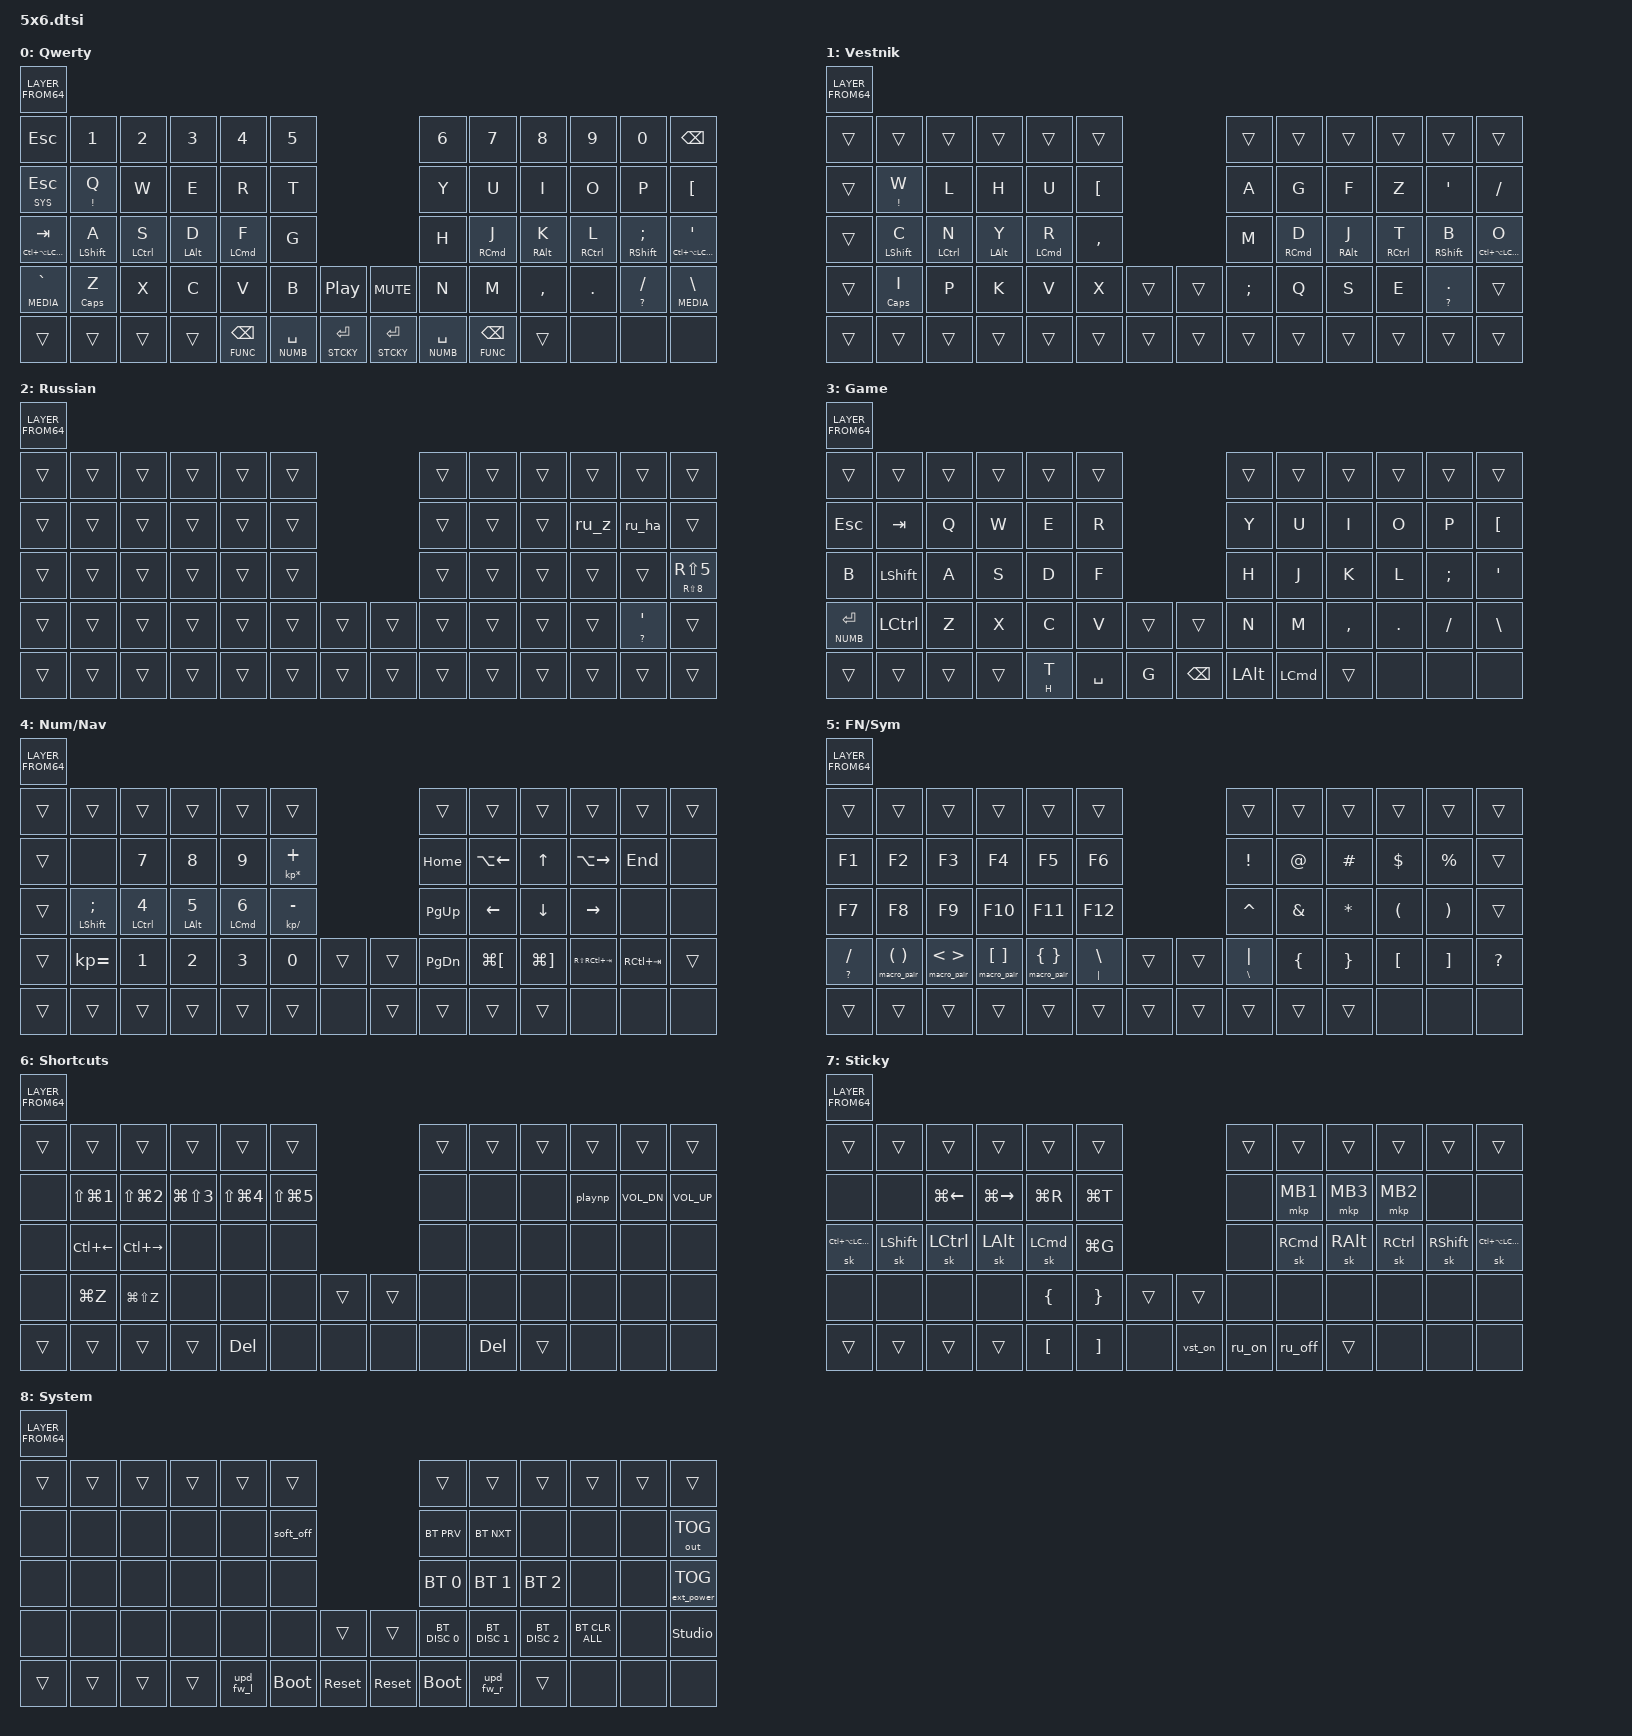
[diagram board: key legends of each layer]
// ZMK includes
#include <behaviors.dtsi>
#include <dt-bindings/zmk/bt.h>
#include <dt-bindings/zmk/ext_power.h>
#include <dt-bindings/zmk/keys.h>
#include <dt-bindings/zmk/pointing.h>
#include <dt-bindings/zmk/outputs.h>

#define ___    &trans
#define DFLT   0
#define VST    1
#define RU     2
#define GAME   3
#define NUMB   4
#define FUNC   5
#define MEDIA  6
#define STCKY  7
#define SYS    8

&lt { quick-tap-ms = <250>; };

&mt {
    hold-trigger-on-release;
    flavor = "balanced";
    quick-tap-ms = <250>;
};

&soft_off { hold-time-ms = <2000>; };

#include "combos.dtsi"
#include "macros.dtsi"
#include "behaviors.dtsi"

/ {
    sensors { triggers-per-rotation = <20>; };
};

/ {
    keymap {
        compatible = "zmk,keymap";

        default_layer {
            label = "Qwerty";
            bindings = < LAYER_FROM64( \
&kp ESCAPE,            &kp N1,        &kp N2,       &kp N3,      &kp N4,         &kp N5,                                              &kp N6,          &kp N7,           &kp N8,      &kp N9,       &kp N0,           &kp BACKSPACE,
&lt SYS ESC,           &mt EXCL Q,    &kp W,        &kp E,       &kp R,          &kp T,                                               &kp Y,           &kp U,            &kp I,       &kp O,        &kp P,            &kp LBKT,
&mt LC(LA(LCMD)) TAB,  &mtl LSHIFT A,  &mtl LCTRL S,  &mtl LALT D,  &mtl LCMD F, &kp G,                                               &kp H,           &mtr RCMD J,       &mtr RALT K,  &mtr RCTRL L,  &mtr RSHIFT SEMI,  &mt LC(LA(LCMD)) SQT,
&lt MEDIA GRAVE,       &mt CAPS Z,    &kp X,        &kp C,       &kp V,          &kp B,           &kp C_PLAY_PAUSE,  &kp K_MUTE,      &kp N,           &kp M,            &kp COMMA,   &kp DOT,      &mt QMARK SLASH,  &lt MEDIA BSLH,
___,                   ___,           ___,          ___,         &lt FUNC BSPC,  &lt NUMB SPACE,  &lt STCKY ENTER,  &lt STCKY ENTER,  &lt NUMB SPACE,  &lt FUNC BSPC,    ___,         &none,        &none,            &none
            )>;
            sensor-bindings =
              <&inc_dec_kp DOWN UP &inc_dec_kp RIGHT LEFT>;
        };

        vestnik {
            label = "Vestnik";
            bindings = < LAYER_FROM64( \
___,  ___,           ___,          ___,         ___,          ___,                   ___,       ___,           ___,         ___,           ___,            ___,
___,  &mt EXCL W,    &kp L,        &kp H,       &kp U,        &kp LBKT,              &kp A,     &kp G,         &kp F,       &kp Z,         &kp SQT,        &kp SLASH,
___,  &mtl LSHIFT C, &mtl LCTRL N, &mtl LALT Y, &mtl LCMD R,  &kp COMMA,             &kp M,     &mtr RCMD D,   &mtr RALT J, &mtr RCTRL T,  &mtr RSHIFT B,  &mt LC(LA(LCMD)) O,
___,  &mt CAPS I,    &kp P,        &kp K,       &kp V,        &kp X,     ___,  ___,  &kp SEMI,  &kp Q,         &kp S,       &kp E,         &mt QMARK DOT,  ___,
___,  ___,           ___,          ___,         ___,          ___,       ___,  ___,  ___,       ___,           ___,         ___,           ___,            ___
            )>;
            sensor-bindings =
              <&inc_dec_kp DOWN UP &inc_dec_kp RIGHT LEFT>;
        };

        ru {
            label = "Russian";
            bindings = < LAYER_FROM64( \
___,  ___,  ___,  ___,  ___,  ___,              ___,  ___,  ___,  ___,     ___,     ___,
___,  ___,  ___,  ___,  ___,  ___,              ___,  ___,  ___,  &ru_z,  &ru_ha,   ___,
___,  ___,  ___,  ___,  ___,  ___,              ___,  ___,  ___,  ___,    ___,      &mt RS(NUMBER_8) RS(NUMBER_5),
___,  ___,  ___,  ___,  ___,  ___,  ___,  ___,  ___,  ___,  ___,  ___,    &mt QMARK APOS,  ___,
___,  ___,  ___,  ___,  ___,  ___,  ___,  ___,  ___,  ___,  ___,  ___,    ___,      ___
            )>;
        };

        game {
            label = "Game";
            bindings = < LAYER_FROM64( \
___,             ___,        ___,     ___,     ___,      ___,                            ___,       ___,       ___,        ___,      ___,       ___,
&kp ESC,         &kp TAB,    &kp Q,   &kp W,   &kp E,    &kp R,                          &kp Y,     &kp U,     &kp I,      &kp O,    &kp P,     &kp LBKT,
&kp B,           &kp LSHFT,  &kp A,   &kp S,   &kp D,    &kp F,                          &kp H,     &kp J,     &kp K,      &kp L,    &kp SEMI,  &kp SQT,
&lt NUMB ENTER,  &kp LCTRL,  &kp Z,   &kp X,   &kp C,    &kp V,      ___,     ___,       &kp N,     &kp M,     &kp COMMA,  &kp DOT,  &kp FSLH,  &kp BSLH,
___,             ___,        ___,     ___,     &mt H T,  &kp SPACE,  &kp G,   &kp BSPC,  &kp LALT,  &kp LCMD,  ___,        &none,    &none,     &none
            )>;
            sensor-bindings =
              <&inc_dec_kp RBKT LBKT>,
              <&inc_dec_kp C_VOLUME_UP C_VOLUME_DOWN>;
        };

        num {
            label = "Num/Nav";
            bindings = < LAYER_FROM64( \
___,     ___,              ___,           ___,          ___,          ___,                                     ___,        ___,           ___,           ___,              ___,          ___,
___,     &none,            &kp N7,        &kp N8,       &kp N9,       &mt KP_ASTERISK PLUS,                    &kp HOME,   &kp LA(LEFT),  &kp UP,        &kp LA(RIGHT),    &kp END,      &none,
___,     &mt LSHIFT SEMI,  &mt LCTRL N4,  &mt LALT N5,  &mt LCMD N6,  &mt KP_DIVIDE MINUS,                     &kp PG_UP,  &kp LEFT,      &kp DOWN,      &kp RIGHT,        &none,        &none,
___,     &kp KP_EQUAL,     &kp N1,        &kp N2,       &kp N3,       &kp N0,                ___,     ___,     &kp PG_DN,  &kp LG(LBKT),  &kp LG(RBKT),  &kp RS(RC(TAB)),  &kp RC(TAB),  ___,
___,     ___,              ___,           ___,          ___,          ___,                   &none,   ___,     ___,        ___,           ___,           &none,            &none,        &none
            )>;
            sensor-bindings =
              <&inc_dec_kp RIGHT LEFT>,
              <&inc_dec_kp UP DOWN>;
        };

        symb {
            label = "FN/Sym";
            bindings = < LAYER_FROM64( \
___,              ___,                    ___,                ___,                    ___,                    ___,                              ___,            ___,       ___,        ___,       ___,          ___,
&kp F1,           &kp F2,                 &kp F3,             &kp F4,                 &kp F5,                 &kp F6,                           &kp EXCL,       &kp AT,    &kp POUND,  &kp DLLR,  &kp PERCENT,  ___,
&kp F7,           &kp F8,                 &kp F9,             &kp F10,                &kp F11,                &kp F12,                          &kp CARET,      &kp AMPS,  &kp ASTRK,  &kp LPAR,  &kp RPAR,     ___,
&mt QMARK SLASH,  &macro_pair LPAR RPAR,  &macro_pair LT GT,  &macro_pair LBKT RBKT,  &macro_pair LBRC RBRC,  &mt PIPE BSLH,  ___,     ___,     &mt BSLH PIPE,  &kp LBRC,  &kp RBRC,   &kp LBKT,  &kp RBKT,     &kp QMARK,
___,              ___,                    ___,                ___,                    ___,                    ___,            ___,     ___,     ___,            ___,       ___,        &none,     &none,        &none
            )>;
        };

        media {
            label = "Shortcuts";
            bindings = < LAYER_FROM64( \
___,     ___,             ___,             ___,             ___,             ___,                               ___,     ___,      ___,     ___,      ___,           ___,
&none,   &kp LS(LG(N1)),  &kp LS(LG(N2)),  &kp LG(LS(N3)),  &kp LS(LG(N4)),  &kp LS(LG(N5)),                    &none,   &none,    &none,   &playnp,  &kp C_VOL_DN,  &kp C_VOL_UP,
&none,   &kp LC(LEFT),    &kp LC(RIGHT),   &none,           &none,           &none,                             &none,   &none,    &none,   &none,    &none,         &none,
&none,   &kp LG(Z),       &kp LG(LS(Z)),   &none,           &none,           &none,           ___,     ___,     &none,   &none,    &none,   &none,    &none,         &none,
___,     ___,             ___,             ___,             &kp DEL,         &none,           &none,   &none,   &none,   &kp DEL,  ___,     &none,    &none,         &none
            )>;
            sensor-bindings =
              <&inc_dec_kp C_VOL_UP C_VOL_DN>,
              <&inc_dec_kp UP_ARROW DOWN>;
        };

        sticky {
            label = "Sticky";
            bindings = < LAYER_FROM64( \
___,               ___,         ___,           ___,            ___,        ___,                            ___,     ___,       ___,       ___,        ___,         ___,
&none,             &none,       &kp LG(LEFT),  &kp LG(RIGHT),  &kp LG(R),  &kp LG(T),                      &none,   &mkp MB1,  &mkp MB3,  &mkp MB2,   &none,       &none,
&sk LC(LA(LCMD)),  &sk LSHIFT,  &sk LCTRL,     &sk LALT,       &sk LCMD,   &kp LG(G),                      &none,   &sk RCMD,  &sk RALT,  &sk RCTRL,  &sk RSHIFT,  &sk LC(LA(LCMD)),
&none,             &none,       &none,         &none,          &kp LBRC,   &kp RBRC,   ___,     ___,       &none,   &none,     &none,     &none,      &none,       &none,
___,               ___,         ___,           ___,            &kp LBKT,   &kp RBKT,   &none,   &vst_on,   &ru_on,  &ru_off,   ___,       &none,      &none,       &none
            )>;
            sensor-bindings =
              <&inc_dec_kp RIGHT LEFT>,
              <&inc_dec_kp UP DOWN>;
        };

        system {
            label = "System";
            bindings = < LAYER_FROM64( \
___,      ___,     ___,     ___,     ___,        ___,                                     ___,            ___,            ___,            ___,             ___,        ___,
&none,    &none,   &none,   &none,   &none,      &soft_off,                               &bt BT_PRV,     &bt BT_NXT,     &none,          &none,           &none,      &out OUT_TOG,
&none,    &none,   &none,   &none,   &none,      &none,                                   &bt BT_SEL 0,   &bt BT_SEL 1,   &bt BT_SEL 2,   &none,           &none,      &ext_power EP_TOG,
&none,    &none,   &none,   &none,   &none,      &none,        ___,          ___,         &bt BT_DISC 0,  &bt BT_DISC 1,  &bt BT_DISC 2,  &bt BT_CLR_ALL,  &none,      &studio_unlock,
___,      ___,     ___,     ___,     &upd_fw_l,  &bootloader,  &sys_reset,   &sys_reset,  &bootloader,    &upd_fw_r,      ___,            &none,           &none,      &none
            )>;
        };
    };
};
